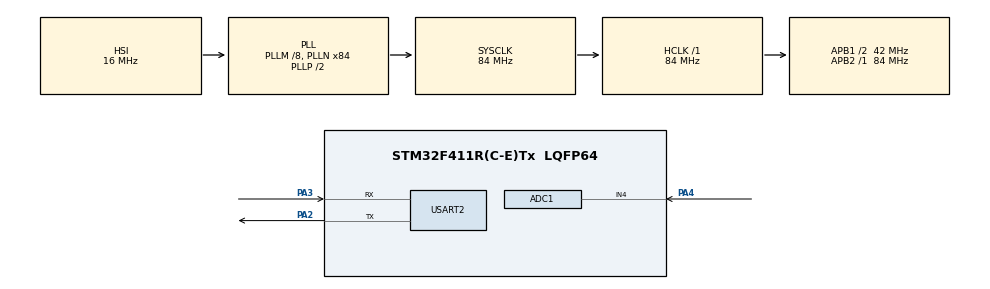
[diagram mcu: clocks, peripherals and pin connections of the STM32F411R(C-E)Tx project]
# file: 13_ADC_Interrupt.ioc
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ADC1.Channel-0\#ChannelRegularConversion=ADC_CHANNEL_4
ADC1.ContinuousConvMode=ENABLE
ADC1.NbrOfConversionFlag=1
ADC1.Rank-0\#ChannelRegularConversion=1
ADC1.SamplingTime-0\#ChannelRegularConversion=ADC_SAMPLETIME_480CYCLES
ADC1.master=1
Mcu.Family=STM32F4
Mcu.Name=STM32F411R(C-E)Tx
Mcu.Package=LQFP64
NVIC.ADC_IRQn=true\:0\:0\:false\:false\:true\:true\:true\:true
NVIC.PriorityGroup=NVIC_PRIORITYGROUP_4
PA13.Mode=Serial_Wire
PA13.Signal=SYS_JTMS-SWDIO
PA14.Mode=Serial_Wire
PA14.Signal=SYS_JTCK-SWCLK
PA2.Mode=Asynchronous
PA2.Signal=USART2_TX
PA3.Mode=Asynchronous
PA3.Signal=USART2_RX
PA4.Signal=ADCx_IN4
ProjectManager.HeapSize=0x200
ProjectManager.StackSize=0x400
ProjectManager.TargetToolchain=STM32CubeIDE
RCC.48MHZClocksFreq_Value=42000000
RCC.AHBFreq_Value=84000000
RCC.APB1CLKDivider=RCC_HCLK_DIV2
RCC.APB1Freq_Value=42000000
RCC.APB1TimFreq_Value=84000000
RCC.APB2Freq_Value=84000000
RCC.APB2TimFreq_Value=84000000
RCC.CortexFreq_Value=84000000
RCC.HCLKFreq_Value=84000000
RCC.HSE_VALUE=25000000
RCC.HSI_VALUE=16000000
RCC.LSE_VALUE=32768
RCC.PLLM=8
RCC.PLLN=84
RCC.SYSCLKFreq_VALUE=84000000
RCC.SYSCLKSource=RCC_SYSCLKSOURCE_PLLCLK
RCC.VCOOutputFreq_Value=168000000
SH.ADCx_IN4.0=ADC1_IN4,IN4
USART2.VirtualMode=VM_ASYNC
board=custom

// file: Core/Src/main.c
/* USER CODE BEGIN Header */
/**
  ******************************************************************************
  * @file           : main.c
  * @brief          : Main program body
  ******************************************************************************
  * @attention
  *
  * Copyright (c) 2024 STMicroelectronics.
  * All rights reserved.
  *
  * This software is licensed under terms that can be found in the LICENSE file
  * in the root directory of this software component.
  * If no LICENSE file comes with this software, it is provided AS-IS.
  *
  ******************************************************************************
  */
/* USER CODE END Header */
#include "main.h"

ADC_HandleTypeDef hadc1;

UART_HandleTypeDef huart2;

/* USER CODE BEGIN PV */
volatile uint16_t uwADCxConvertedValue;
/* USER CODE END PV */

void SystemClock_Config(void);
static void MX_GPIO_Init(void);
static void MX_ADC1_Init(void);
static void MX_USART2_UART_Init(void);
/* USER CODE BEGIN PFP */
#ifdef __GNUC__
#define PUTCHAR_PROTOTYPE int __io_putchar(int ch)
#else
#define PUTCHAR_PROTOTYPE int fputc(int ch, FILE *f)
#endif /* __GNUC__ */

/**
  * @brief  Retargets the C library printf function to the USART.
  * @param  None
  * @retval None
  */
PUTCHAR_PROTOTYPE
{
  /* Place your implementation of fputc here */
  /* e.g. write a character to the UART2 and Loop until the end of transmission */
  if (ch == '\n')
    HAL_UART_Transmit (&huart2, (uint8_t*) "\r", 1, 0xFFFF);
  HAL_UART_Transmit (&huart2, (uint8_t*) &ch, 1, 0xFFFF);

  return ch;
}
/* USER CODE END PFP */

int main(void)
{

  /* MCU Configuration--------------------------------------------------------*/

  /* Reset of all peripherals, Initializes the Flash interface and the Systick. */
  HAL_Init();

  /* Configure the system clock */
  SystemClock_Config();

  /* Initialize all configured peripherals */
  MX_GPIO_Init();
  MX_ADC1_Init();
  MX_USART2_UART_Init();

  /* Infinite loop */
  /* USER CODE BEGIN WHILE */
  if (HAL_ADC_Start_IT (&hadc1) != HAL_OK)
    {
      Error_Handler ();
    }

  while (1)
  {
	  printf ("TEMP=%4d\n", uwADCxConvertedValue);
	  HAL_Delay (100);
    /* USER CODE END WHILE */

  }
}

void SystemClock_Config(void)
{
  RCC_OscInitTypeDef RCC_OscInitStruct = {0};
  RCC_ClkInitTypeDef RCC_ClkInitStruct = {0};

  /** Configure the main internal regulator output voltage
  */
  __HAL_RCC_PWR_CLK_ENABLE();
  __HAL_PWR_VOLTAGESCALING_CONFIG(PWR_REGULATOR_VOLTAGE_SCALE1);

  /** Initializes the RCC Oscillators according to the specified parameters
  * in the RCC_OscInitTypeDef structure.
  */
  RCC_OscInitStruct.OscillatorType = RCC_OSCILLATORTYPE_HSI;
  RCC_OscInitStruct.HSIState = RCC_HSI_ON;
  RCC_OscInitStruct.HSICalibrationValue = RCC_HSICALIBRATION_DEFAULT;
  RCC_OscInitStruct.PLL.PLLState = RCC_PLL_ON;
  RCC_OscInitStruct.PLL.PLLSource = RCC_PLLSOURCE_HSI;
  RCC_OscInitStruct.PLL.PLLM = 8;
  RCC_OscInitStruct.PLL.PLLN = 84;
  RCC_OscInitStruct.PLL.PLLP = RCC_PLLP_DIV2;
  RCC_OscInitStruct.PLL.PLLQ = 4;
  if (HAL_RCC_OscConfig(&RCC_OscInitStruct) != HAL_OK)
  {
    Error_Handler();
  }

  /** Initializes the CPU, AHB and APB buses clocks
  */
  RCC_ClkInitStruct.ClockType = RCC_CLOCKTYPE_HCLK|RCC_CLOCKTYPE_SYSCLK
                              |RCC_CLOCKTYPE_PCLK1|RCC_CLOCKTYPE_PCLK2;
  RCC_ClkInitStruct.SYSCLKSource = RCC_SYSCLKSOURCE_PLLCLK;
  RCC_ClkInitStruct.AHBCLKDivider = RCC_SYSCLK_DIV1;
  RCC_ClkInitStruct.APB1CLKDivider = RCC_HCLK_DIV2;
  RCC_ClkInitStruct.APB2CLKDivider = RCC_HCLK_DIV1;

  if (HAL_RCC_ClockConfig(&RCC_ClkInitStruct, FLASH_LATENCY_2) != HAL_OK)
  {
    Error_Handler();
  }
}

static void MX_ADC1_Init(void)
{

  ADC_ChannelConfTypeDef sConfig = {0};

  /** Configure the global features of the ADC (Clock, Resolution, Data Alignment and number of conversion)
  */
  hadc1.Instance = ADC1;
  hadc1.Init.ClockPrescaler = ADC_CLOCK_SYNC_PCLK_DIV4;
  hadc1.Init.Resolution = ADC_RESOLUTION_12B;
  hadc1.Init.ScanConvMode = DISABLE;
  hadc1.Init.ContinuousConvMode = ENABLE;
  hadc1.Init.DiscontinuousConvMode = DISABLE;
  hadc1.Init.ExternalTrigConvEdge = ADC_EXTERNALTRIGCONVEDGE_NONE;
  hadc1.Init.ExternalTrigConv = ADC_SOFTWARE_START;
  hadc1.Init.DataAlign = ADC_DATAALIGN_RIGHT;
  hadc1.Init.NbrOfConversion = 1;
  hadc1.Init.DMAContinuousRequests = DISABLE;
  hadc1.Init.EOCSelection = ADC_EOC_SINGLE_CONV;
  if (HAL_ADC_Init(&hadc1) != HAL_OK)
  {
    Error_Handler();
  }

  /** Configure for the selected ADC regular channel its corresponding rank in the sequencer and its sample time.
  */
  sConfig.Channel = ADC_CHANNEL_4;
  sConfig.Rank = 1;
  sConfig.SamplingTime = ADC_SAMPLETIME_480CYCLES;
  if (HAL_ADC_ConfigChannel(&hadc1, &sConfig) != HAL_OK)
  {
    Error_Handler();
  }

}

static void MX_USART2_UART_Init(void)
{

  huart2.Instance = USART2;
  huart2.Init.BaudRate = 115200;
  huart2.Init.WordLength = UART_WORDLENGTH_8B;
  huart2.Init.StopBits = UART_STOPBITS_1;
  huart2.Init.Parity = UART_PARITY_NONE;
  huart2.Init.Mode = UART_MODE_TX_RX;
  huart2.Init.HwFlowCtl = UART_HWCONTROL_NONE;
  huart2.Init.OverSampling = UART_OVERSAMPLING_16;
  if (HAL_UART_Init(&huart2) != HAL_OK)
  {
    Error_Handler();
  }

}

static void MX_GPIO_Init(void)
{

  /* GPIO Ports Clock Enable */
  __HAL_RCC_GPIOA_CLK_ENABLE();

}

/* USER CODE BEGIN 4 */
void HAL_ADC_ConvCpltCallback(ADC_HandleTypeDef *AdcHandle)
{
	uwADCxConvertedValue = HAL_ADC_GetValue(AdcHandle);
}
/* USER CODE END 4 */

void Error_Handler(void)
{
  __disable_irq();
  while (1)
  {
  }
}
